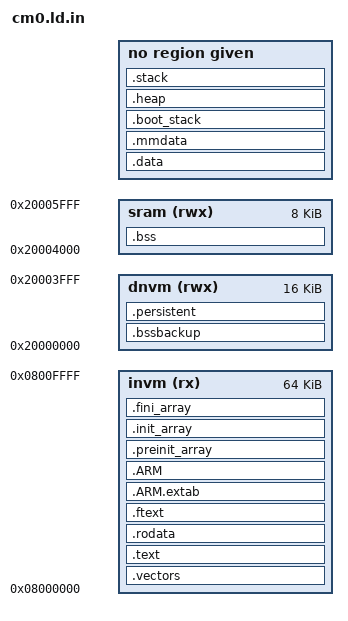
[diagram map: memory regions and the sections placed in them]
/*
 * Copyright (c) 2020, Arm Limited and Contributors.
 * All rights reserved.
 *
 * SPDX-License-Identifier: BSD-3-Clause
 */

EXTERN (_vectors)
EXTERN (__VECTOR_TABLE)
ENTRY(Reset_Handler)

__stack_size = 0x200;
__boot_stack_size = 0x40;

MEMORY
{
        invm (rx)   : ORIGIN = 0x08000000, LENGTH = 64K
        dnvm (rwx): ORIGIN = 0x20000000, LENGTH = 16K
        sram (rwx) : ORIGIN = 0x20000000 + 16K, LENGTH = 8K
}

/* Define sections. */
SECTIONS
{

  .vectors : {
    . = ALIGN(4);
    KEEP(*(.vectors)) /* Vector table */
  } >invm

  .text : {
    . = ALIGN(4);
    *(.text*)   /* Program code */
    *(.text.*)
    *(.glue_7)
    *(.glue_7t)
    *(.eh_frame)

    KEEP (*(.init))
    KEEP (*(.fini))
    . = ALIGN(4);
    .etext = .;
  } >invm

  .rodata : {
    . = ALIGN(4);
    *(.rodata*)  /* Read-only data */
    *(.rodata.*) /* Read-only data */
    . = ALIGN(4);
  } >invm

  .ftext : {
    . = ALIGN(4);
    *(.ftext)
    . = ALIGN(4);
  } >invm

  .ARM.extab : { *(.ARM.extab* .gnu.linkonce.armextab.*) } >invm
  .ARM : {
    __exidx_start = .;
    *(.ARM.exidx*)
    __exidx_end = .;
  } >invm

  .preinit_array : {
    __preinit_array_start = .;
    KEEP (*(.preinit_array*))
    __preinit_array_end = .;
  } >invm

  .init_array : {
    __init_array_start = .;
    KEEP (*(SORT(.init_array.*)))
    KEEP (*(.init_array))
    __init_array_end = .;
  } >invm

  .fini_array : {
    __fini_array_start = .;
    KEEP (*(.fini_array))
    KEEP (*(SORT(.fini_array.*)))
    __fini_array_end = .;
  } >invm

  .bss : {
     __bss_start__ = .;
    PROVIDE(__bss_low = .);
    *(.bss)
    *(.bss*)
    *(COMMON)
    _ebss = .;
    __bss_end__ = .;
    PROVIDE(__bss_high = .);
  } > sram

  .bssbackup : {
    PROVIDE(__bss_loadLow = .);
    . += SIZEOF(.bss);
    PROVIDE(__bss_loadHigh = .);
  } > dnvm

  .data : {
    _data = .;
    _sidata = .;
    PROVIDE(__data_low = .);
    . = ALIGN(4);
    *(.data*)   /* Read-write initialized data */
    . = ALIGN(4);
    _edata = .;
    PROVIDE(__data_high = .);
  } > @LD_DATA_ALLOC@

  _data_loadaddr = LOADADDR(.data);
  PROVIDE(__data_loadLow = LOADADDR(.data));
  PROVIDE(__data_loadHigh = LOADADDR(.data) + SIZEOF(.data));

  .mmdata : {
    PROVIDE(__mmdata_low = .);
    . = ALIGN(4);
    *(.mmdata*)   /* Read-write initialized data */
    . = ALIGN(4);
    PROVIDE(__mmdata_high = .);
  } > @LD_MMDATA_ALLOC@

  _mmdata_loadaddr = LOADADDR(.mmdata);
  PROVIDE(__mmdata_loadLow = LOADADDR(.mmdata));
  PROVIDE(__mmdata_loadHigh = LOADADDR(.mmdata) + SIZEOF(.mmdata));

  /* Section for persistent/nonvolatile variables */
  .persistent : {
    PROVIDE(__persistent_low = .);
    . = ALIGN(4);
    *(.persistent*)   /* Read-write initialized data */
    . = ALIGN(4);
    PROVIDE(__persistent_high = .);
  } > dnvm

  /* Small stack for use when booting/restoring context */
  .boot_stack (NOLOAD) :
  {
    PROVIDE(__boot_stack_low = .);
    . = ALIGN(4);
    *(.stack)
    . += __boot_stack_size;
    PROVIDE(__boot_stack_high = .);
  } > @LD_BOOT_STACK_ALLOC@


  .heap (NOLOAD) :
  {
    . = ALIGN(2);
    __heap_start__ = .;
    KEEP (*(.heap))
    _end = .;
    PROVIDE (end = .);
    /* This word is here so that the section is not empty, and thus
       not discarded by the linker.  The actual value does not matter
       and is ignored.  */
    LONG(0);
    __heap_end__ = .;
    __HeapLimit = __heap_end__;
  } > @LD_HEAP_ALLOC@


  .stack (ORIGIN (@LD_STACK_ALLOC@) + LENGTH(@LD_STACK_ALLOC@) - __stack_size) :
  {
    . = ALIGN(4);
    PROVIDE (__stack = .);
    __stack_low = .;
    *(.stack)
    . += __stack_size;
    __stack_high = .;
    PROVIDE (__STACK_END = .);
  }
  PROVIDE(_stack = ORIGIN(sram) + LENGTH(sram));
  PROVIDE(_stacktop = _stack);

  . = ALIGN(4);
  end = .;

  /* Remove information finvm standard libraries */
  /DISCARD/ :
  {
    libc.a ( * )
    libm.a ( * )
    libgcc.a ( * )
  }

  .ARM.attributes 0 : { *(.ARM.attributes)}
}
